AUTOSAR XML (schema 4-1-2)
package /MICROSAR_SWCS_DEV/ComM_swc/ComponentTypes
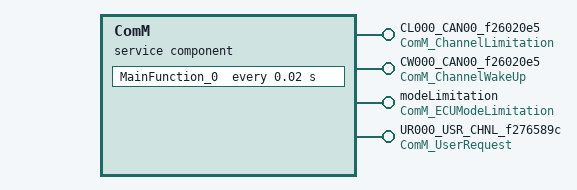
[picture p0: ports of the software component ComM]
  service sw component type ComM
    4 x provide port:
      CL000_CAN00_f26020e5: provided-com-specs=[{operation=GetInhibitionStatus, queue-length=1}, {operation=LimitChannelToNoComMode, queue-length=1}], provided-interface=ComM_ChannelLimitation
      CW000_CAN00_f26020e5: provided-com-specs=[{operation=GetInhibitionStatus, queue-length=1}, {operation=PreventWakeUp, queue-length=1}], provided-interface=ComM_ChannelWakeUp
      modeLimitation: provided-interface=ComM_ECUModeLimitation
        provided-com-specs:
          operation=LimitECUToNoComMode, queue-length=1
          operation=ReadInhibitCounter, queue-length=1
          operation=ResetInhibitCounter, queue-length=1
          operation=SetECUGroupClassification, queue-length=1
      UR000_USR_CHNL_f276589c: provided-interface=ComM_UserRequest
        provided-com-specs:
          operation=GetCurrentComMode, queue-length=1
          operation=GetMaxComMode, queue-length=1
          operation=GetRequestedComMode, queue-length=1
          operation=RequestComMode, queue-length=1
    behavior ComMInternalBehavior: included-data-type-set=data-type=[NetworkHandleType, ComM_UserHandleType, ComM_ModeType, ComM_InhibitionStatusType]
      7 x operation invoked event:
        OpEventGetCurrentComMode_GetCurrentComMode_UR000_USR_CHNL_f276589c: start-on-event=GetCurrentComMode, operation=UR000_USR_CHNL_f276589c.GetCurrentComMode
        OpEventGetInhibitionStatus_GetInhibitionStatus_CL000_CAN00_f26020e5: start-on-event=GetInhibitionStatus, operation=CL000_CAN00_f26020e5.GetInhibitionStatus
        OpEventGetInhibitionStatus_GetInhibitionStatus_CW000_CAN00_f26020e5: start-on-event=GetInhibitionStatus, operation=CW000_CAN00_f26020e5.GetInhibitionStatus
        OpEventGetMaxComMode_GetMaxComMode_UR000_USR_CHNL_f276589c: start-on-event=GetMaxComMode, operation=UR000_USR_CHNL_f276589c.GetMaxComMode
        OpEventGetRequestedComMode_GetRequestedComMode_UR000_USR_CHNL_f276589c: start-on-event=GetRequestedComMode, operation=UR000_USR_CHNL_f276589c.GetRequestedComMode
        OpEventLimitChannelToNoComMode_LimitChannelToNoComMode_CL000_CAN00_f26020e5: start-on-event=LimitChannelToNoComMode, operation=CL000_CAN00_f26020e5.LimitChannelToNoComMode
        OpEventLimitECUToNoComMode_LimitECUToNoComMode_modeLimitation: start-on-event=LimitECUToNoComMode, operation=modeLimitation.LimitECUToNoComMode
      timing event Timer_MainFunction_0: start-on-event=MainFunction_0, period=0.02
      5 x operation invoked event:
        OpEventPreventWakeUp_PreventWakeUp_CW000_CAN00_f26020e5: start-on-event=PreventWakeUp, operation=CW000_CAN00_f26020e5.PreventWakeUp
        OpEventReadInhibitCounter_ReadInhibitCounter_modeLimitation: start-on-event=ReadInhibitCounter, operation=modeLimitation.ReadInhibitCounter
        OpEventRequestComMode_RequestComMode_UR000_USR_CHNL_f276589c: start-on-event=RequestComMode, operation=UR000_USR_CHNL_f276589c.RequestComMode
        OpEventResetInhibitCounter_ResetInhibitCounter_modeLimitation: start-on-event=ResetInhibitCounter, operation=modeLimitation.ResetInhibitCounter
        OpEventSetECUGroupClassification_SetECUGroupClassification_modeLimitation: start-on-event=SetECUGroupClassification, operation=modeLimitation.SetECUGroupClassification
      port-api-options:
        {enable-take-address=true, indirect-api=false, port-defined-argument-value{value=CL000_CAN00_f26020e5_0:0, value-type=NetworkHandleType}, port=CL000_CAN00_f26020e5}
        {enable-take-address=true, indirect-api=false, port-defined-argument-value{value=CW000_CAN00_f26020e5_0:0, value-type=NetworkHandleType}, port=CW000_CAN00_f26020e5}
        enable-take-address=true, indirect-api=false, port=modeLimitation
        {enable-take-address=true, indirect-api=false, port-defined-argument-value{value=UR000_USR_CHNL_f276589c_0:0, value-type=ComM_UserHandleType}, port=UR000_USR_CHNL_f276589c}
      12 x runnable, all with can-be-invoked-concurrently=true:
        GetCurrentComMode: symbol=ComM_GetCurrentComMode
        GetInhibitionStatus: symbol=ComM_GetInhibitionStatus
        GetMaxComMode: symbol=ComM_GetMaxComMode
        GetRequestedComMode: symbol=ComM_GetRequestedComMode
        LimitChannelToNoComMode: symbol=ComM_LimitChannelToNoComMode
        LimitECUToNoComMode: symbol=ComM_LimitECUToNoComMode
        MainFunction_0: symbol=ComM_MainFunction_0
        PreventWakeUp: symbol=ComM_PreventWakeUp
        ReadInhibitCounter: symbol=ComM_ReadInhibitCounter
        RequestComMode: symbol=ComM_RequestComMode
        ResetInhibitCounter: symbol=ComM_ResetInhibitCounter
        SetECUGroupClassification: symbol=ComM_SetECUGroupClassification
  swc implementation ComMImplementation: behavior=ComMInternalBehavior
    code-descriptors:
      code Default: artifact-descriptors=autosar-engineering-object={short-label=Default, category=SWSRC}
